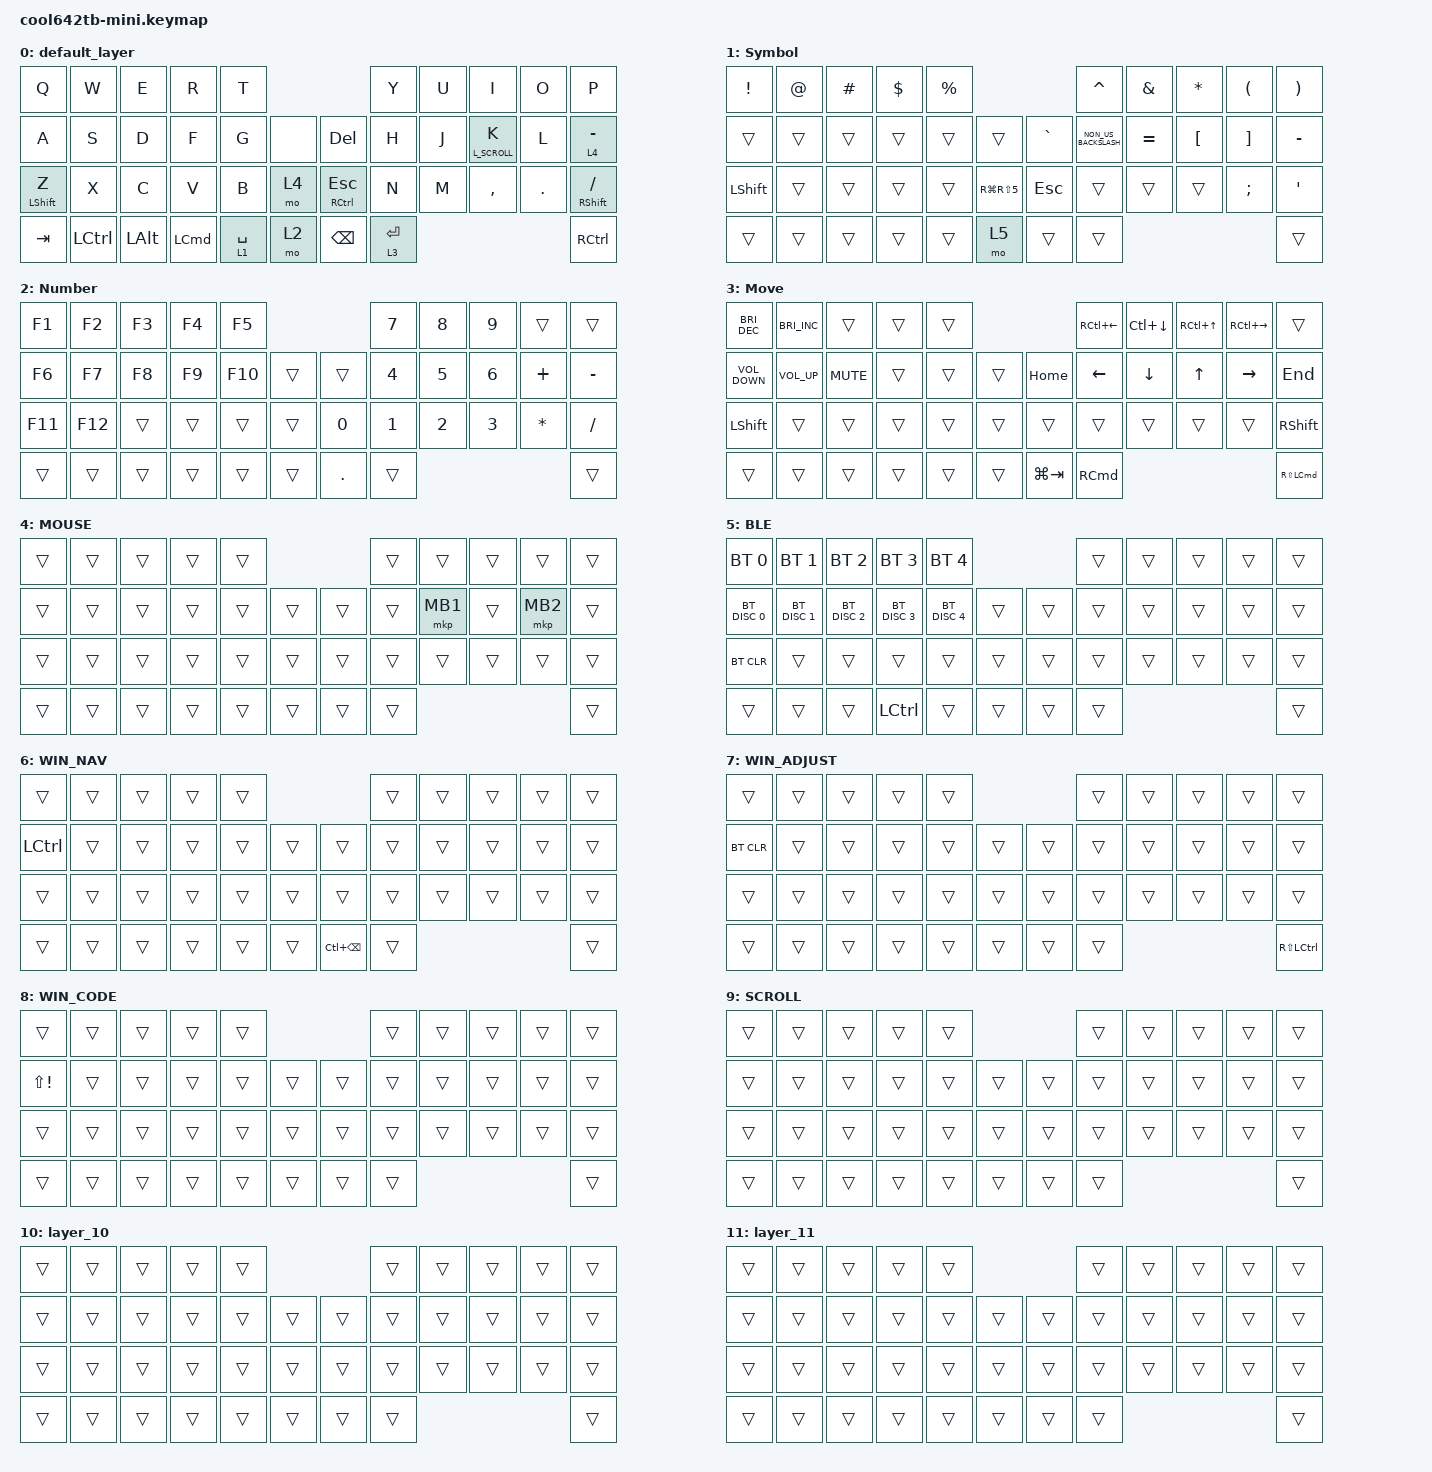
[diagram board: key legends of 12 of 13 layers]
#include <behaviors.dtsi>
#include <dt-bindings/zmk/bt.h>
#include <dt-bindings/zmk/keys.h>
#include <dt-bindings/zmk/pointing.h>

#define L_NAV 1
#define L_CODE 2
#define L_ADJUST 3
#define L_MOUSE 4
#define L_WINDOWS 5
#define L_WIN_NAV 6
#define L_WIN_ADJUST 7
#define L_WIN_CODE 8
#define L_SCROLL 9
#define ZMK_POINTING_DEFAULT_SCRL_VAL 80

&mt {
    flavor = "balanced";
    quick-tap-ms = <0>;
    tapping-term-ms = <180>;
};

/ {
    conditional_layers {
        compatible = "zmk,conditional-layers";

        windows_nav {
            if-layers = <5 1>;
            then-layer = <6>;
        };

        windows_adjust {
            if-layers = <5 3>;
            then-layer = <7>;
        };

        windows_code {
            if-layers = <5 2>;
            then-layer = <8>;
        };
    };

    combos {
        compatible = "zmk,combos";

        shift_tab {
            bindings = <&kp LANG2>;
            key-positions = <12 13>;
        };

        lang {
            bindings = <&kp LANG1>;
            key-positions = <18 19>;
        };
    };

    behaviors {
        encoder_msc_down_up: encoder_msc_down_up {
            compatible = "zmk,behavior-sensor-rotate";
            label = "ENCODER_MSC_DOWN_UP";
            #sensor-binding-cells = <0>;
            bindings = <&msc SCRL_UP>, <&msc SCRL_DOWN>;

            tap-ms = <20>;
        };
    };

    keymap {
        compatible = "zmk,keymap";

        default_layer {
            bindings = <
&kp Q             &kp W      &kp E         &kp R             &kp T                                     &kp Y        &kp U  &kp I           &kp O    &kp P
&kp A             &kp S      &kp D         &kp F             &kp G        &none      &kp DELETE        &kp H        &kp J  &lt L_SCROLL K  &kp L    &lt 4 MINUS
&mt LEFT_SHIFT Z  &kp X      &kp C         &kp V             &kp B        &mo 4      &mt RCTRL ESCAPE  &kp N        &kp M  &kp COMMA       &kp DOT  &mt RSHIFT SLASH
&kp TAB           &kp LCTRL  &kp LEFT_ALT  &kp LEFT_COMMAND  &lt 1 SPACE  &mo 2      &kp BACKSPACE     &lt 3 ENTER                                  &kp RIGHT_CONTROL
            >;

            sensor-bindings = <&encoder_msc_down_up>;
        };

        Symbol {
            bindings = <
&kp EXCLAMATION  &kp AT_SIGN  &kp HASH  &kp DOLLAR  &kp PERCENT                                        &kp CARET             &kp AMPERSAND  &kp ASTERISK      &kp LEFT_PARENTHESIS  &kp RIGHT_PARENTHESIS
&trans           &trans       &trans    &trans      &trans       &trans                    &kp GRAVE   &kp NON_US_BACKSLASH  &kp EQUAL      &kp LEFT_BRACKET  &kp RIGHT_BRACKET     &kp MINUS
&kp LEFT_SHIFT   &trans       &trans    &trans      &trans       &kp RG(RS(NUMBER_5))      &kp ESCAPE  &trans                &trans         &trans            &kp SEMICOLON         &kp SQT
&trans           &trans       &trans    &trans      &trans       &mo 5                     &trans      &trans                                                                       &trans
            >;
        };

        Number {
            bindings = <
&kp F1   &kp F2   &kp F3  &kp F4  &kp F5                             &kp N7        &kp N8        &kp N9        &trans        &trans
&kp F6   &kp F7   &kp F8  &kp F9  &kp F10  &trans      &trans        &kp NUMBER_4  &kp N5        &kp NUMBER_6  &kp PLUS      &kp MINUS
&kp F11  &kp F12  &trans  &trans  &trans   &trans      &kp NUMBER_0  &kp NUMBER_1  &kp NUMBER_2  &kp NUMBER_3  &kp ASTERISK  &kp SLASH
&trans   &trans   &trans  &trans  &trans   &trans      &kp PERIOD    &trans                                                  &trans
            >;
        };

        Move {
            bindings = <
&kp C_BRIGHTNESS_DEC  &kp C_BRIGHTNESS_INC  &trans      &trans  &trans                           &kp RC(LEFT_ARROW)  &kp LC(DOWN_ARROW)  &kp RC(UP_ARROW)  &kp RC(RIGHT_ARROW)  &trans
&kp C_VOLUME_DOWN     &kp C_VOLUME_UP       &kp K_MUTE  &trans  &trans  &trans      &kp HOME     &kp LEFT_ARROW      &kp DOWN            &kp UP_ARROW      &kp RIGHT            &kp END
&kp LEFT_SHIFT        &trans                &trans      &trans  &trans  &trans      &trans       &trans              &trans              &trans            &trans               &kp RIGHT_SHIFT
&trans                &trans                &trans      &trans  &trans  &trans      &kp LG(TAB)  &kp RIGHT_COMMAND                                                              &kp RS(LEFT_COMMAND)
            >;

            sensor-bindings = <&inc_dec_kp LC(PAGE_UP) LC(PAGE_DOWN)>;
        };

        MOUSE {
            bindings = <
&trans  &trans  &trans  &trans  &trans                      &trans  &trans    &trans  &trans    &trans
&trans  &trans  &trans  &trans  &trans  &trans      &trans  &trans  &mkp MB1  &trans  &mkp MB2  &trans
&trans  &trans  &trans  &trans  &trans  &trans      &trans  &trans  &trans    &trans  &trans    &trans
&trans  &trans  &trans  &trans  &trans  &trans      &trans  &trans                              &trans
            >;
        };

        BLE {
            bindings = <
&bt BT_SEL 0   &bt BT_SEL 1   &bt BT_SEL 2   &bt BT_SEL 3      &bt BT_SEL 4                       &trans  &trans  &trans  &trans  &trans
&bt BT_DISC 0  &bt BT_DISC 1  &bt BT_DISC 2  &bt BT_DISC 3     &bt BT_DISC 4  &trans      &trans  &trans  &trans  &trans  &trans  &trans
&bt BT_CLR     &trans         &trans         &trans            &trans         &trans      &trans  &trans  &trans  &trans  &trans  &trans
&trans         &trans         &trans         &kp LEFT_CONTROL  &trans         &trans      &trans  &trans                          &trans
            >;
        };

        WIN_NAV {
            bindings = <
&trans            &trans  &trans  &trans  &trans                                 &trans  &trans  &trans  &trans  &trans
&kp LEFT_CONTROL  &trans  &trans  &trans  &trans  &trans      &trans             &trans  &trans  &trans  &trans  &trans
&trans            &trans  &trans  &trans  &trans  &trans      &trans             &trans  &trans  &trans  &trans  &trans
&trans            &trans  &trans  &trans  &trans  &trans      &kp LC(BACKSPACE)  &trans                          &trans
            >;
        };

        WIN_ADJUST {
            bindings = <
&trans      &trans  &trans  &trans  &trans                      &trans  &trans  &trans  &trans  &trans
&bt BT_CLR  &trans  &trans  &trans  &trans  &trans      &trans  &trans  &trans  &trans  &trans  &trans
&trans      &trans  &trans  &trans  &trans  &trans      &trans  &trans  &trans  &trans  &trans  &trans
&trans      &trans  &trans  &trans  &trans  &trans      &trans  &trans                          &kp RS(LEFT_CONTROL)
            >;
        };

        WIN_CODE {
            bindings = <
&trans        &trans  &trans  &trans  &trans                      &trans  &trans  &trans  &trans  &trans
&kp LS(EXCL)  &trans  &trans  &trans  &trans  &trans      &trans  &trans  &trans  &trans  &trans  &trans
&trans        &trans  &trans  &trans  &trans  &trans      &trans  &trans  &trans  &trans  &trans  &trans
&trans        &trans  &trans  &trans  &trans  &trans      &trans  &trans                          &trans
            >;
        };

        SCROLL {
            bindings = <
&trans  &trans  &trans  &trans  &trans                      &trans  &trans  &trans  &trans  &trans
&trans  &trans  &trans  &trans  &trans  &trans      &trans  &trans  &trans  &trans  &trans  &trans
&trans  &trans  &trans  &trans  &trans  &trans      &trans  &trans  &trans  &trans  &trans  &trans
&trans  &trans  &trans  &trans  &trans  &trans      &trans  &trans                          &trans
            >;
        };

        layer_10 {
            bindings = <
&trans  &trans  &trans  &trans  &trans                      &trans  &trans  &trans  &trans  &trans
&trans  &trans  &trans  &trans  &trans  &trans      &trans  &trans  &trans  &trans  &trans  &trans
&trans  &trans  &trans  &trans  &trans  &trans      &trans  &trans  &trans  &trans  &trans  &trans
&trans  &trans  &trans  &trans  &trans  &trans      &trans  &trans                          &trans
            >;
        };

        layer_11 {
            bindings = <
&trans  &trans  &trans  &trans  &trans                      &trans  &trans  &trans  &trans  &trans
&trans  &trans  &trans  &trans  &trans  &trans      &trans  &trans  &trans  &trans  &trans  &trans
&trans  &trans  &trans  &trans  &trans  &trans      &trans  &trans  &trans  &trans  &trans  &trans
&trans  &trans  &trans  &trans  &trans  &trans      &trans  &trans                          &trans
            >;
        };

        layer_12 {
            bindings = <
&trans  &trans  &trans  &trans  &trans                      &trans  &trans  &trans  &trans  &trans
&trans  &trans  &trans  &trans  &trans  &trans      &trans  &trans  &trans  &trans  &trans  &trans
&trans  &trans  &trans  &trans  &trans  &trans      &trans  &trans  &trans  &trans  &trans  &trans
&trans  &trans  &trans  &trans  &trans  &trans      &trans  &trans                          &trans
            >;
        };
    };
};
